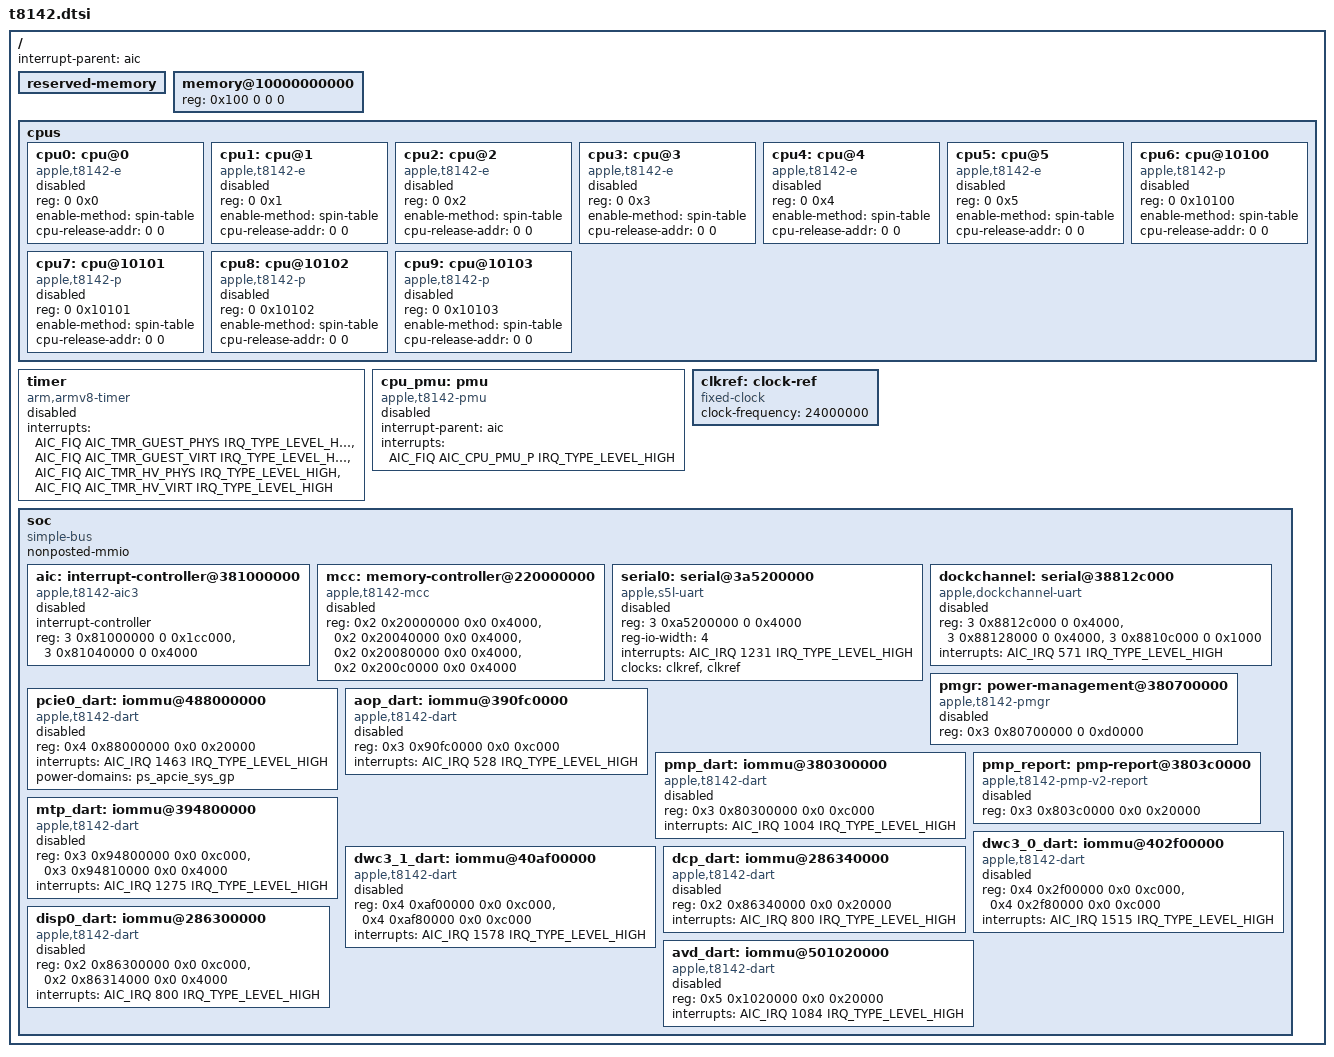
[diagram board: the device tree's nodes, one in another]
// SPDX-License-Identifier: GPL-2.0+ OR MIT
/*
 * Common hardware inventory for boards without a qualified boot profile.
 * Firmware fills RAM and CPU release addresses. Keep new devices disabled;
 * CPU harvesting, firmware handoff and enables need separate qualification.
 */
#include <dt-bindings/interrupt-controller/apple-aic.h>
#include <dt-bindings/interrupt-controller/irq.h>

/ {
	#address-cells = <2>;
	#size-cells = <2>;
	interrupt-parent = <&aic>;

	reserved-memory {
		#address-cells = <2>;
		#size-cells = <2>;
		ranges;
	};

	memory@10000000000 {
		device_type = "memory";
		reg = <0x100 0 0 0>; /* Filled by the loader. */
	};

	cpus {
		#address-cells = <2>;
		#size-cells = <0>;

		cpu0: cpu@0 {
			status = "disabled";
			compatible = "apple,t8142-e";
			device_type = "cpu";
			reg = <0 0x0>;
			enable-method = "spin-table";
			cpu-release-addr = <0 0>; /* Filled by the loader. */
			#cooling-cells = <2>;
		};

		cpu1: cpu@1 {
			status = "disabled";
			compatible = "apple,t8142-e";
			device_type = "cpu";
			reg = <0 0x1>;
			enable-method = "spin-table";
			cpu-release-addr = <0 0>; /* Filled by the loader. */
			#cooling-cells = <2>;
		};

		cpu2: cpu@2 {
			status = "disabled";
			compatible = "apple,t8142-e";
			device_type = "cpu";
			reg = <0 0x2>;
			enable-method = "spin-table";
			cpu-release-addr = <0 0>; /* Filled by the loader. */
			#cooling-cells = <2>;
		};

		cpu3: cpu@3 {
			status = "disabled";
			compatible = "apple,t8142-e";
			device_type = "cpu";
			reg = <0 0x3>;
			enable-method = "spin-table";
			cpu-release-addr = <0 0>; /* Filled by the loader. */
			#cooling-cells = <2>;
		};

		cpu4: cpu@4 {
			status = "disabled";
			compatible = "apple,t8142-e";
			device_type = "cpu";
			reg = <0 0x4>;
			enable-method = "spin-table";
			cpu-release-addr = <0 0>; /* Filled by the loader. */
			#cooling-cells = <2>;
		};

		cpu5: cpu@5 {
			status = "disabled";
			compatible = "apple,t8142-e";
			device_type = "cpu";
			reg = <0 0x5>;
			enable-method = "spin-table";
			cpu-release-addr = <0 0>; /* Filled by the loader. */
			#cooling-cells = <2>;
		};

		cpu6: cpu@10100 {
			status = "disabled";
			compatible = "apple,t8142-p";
			device_type = "cpu";
			reg = <0 0x10100>;
			enable-method = "spin-table";
			cpu-release-addr = <0 0>; /* Filled by the loader. */
			#cooling-cells = <2>;
		};

		cpu7: cpu@10101 {
			status = "disabled";
			compatible = "apple,t8142-p";
			device_type = "cpu";
			reg = <0 0x10101>;
			enable-method = "spin-table";
			cpu-release-addr = <0 0>; /* Filled by the loader. */
			#cooling-cells = <2>;
		};

		cpu8: cpu@10102 {
			status = "disabled";
			compatible = "apple,t8142-p";
			device_type = "cpu";
			reg = <0 0x10102>;
			enable-method = "spin-table";
			cpu-release-addr = <0 0>; /* Filled by the loader. */
			#cooling-cells = <2>;
		};

		cpu9: cpu@10103 {
			status = "disabled";
			compatible = "apple,t8142-p";
			device_type = "cpu";
			reg = <0 0x10103>;
			enable-method = "spin-table";
			cpu-release-addr = <0 0>; /* Filled by the loader. */
			#cooling-cells = <2>;
		};
	};

	timer {
		status = "disabled";
		compatible = "arm,armv8-timer";
		interrupts = <AIC_FIQ AIC_TMR_GUEST_PHYS IRQ_TYPE_LEVEL_HIGH>,
			     <AIC_FIQ AIC_TMR_GUEST_VIRT IRQ_TYPE_LEVEL_HIGH>,
			     <AIC_FIQ AIC_TMR_HV_PHYS IRQ_TYPE_LEVEL_HIGH>,
			     <AIC_FIQ AIC_TMR_HV_VIRT IRQ_TYPE_LEVEL_HIGH>;
		interrupt-names = "phys", "virt", "hyp-phys", "hyp-virt";
	};

	cpu_pmu: pmu {
		status = "disabled";
		compatible = "apple,t8142-pmu";
		interrupt-parent = <&aic>;
		/* The AIC raises both clusters' PMU FIQs as this one, as on T8140. */
		interrupts = <AIC_FIQ AIC_CPU_PMU_P IRQ_TYPE_LEVEL_HIGH>;
	};

	clkref: clock-ref {
		compatible = "fixed-clock";
		#clock-cells = <0>;
		clock-frequency = <24000000>;
	};

	soc {
		compatible = "simple-bus";
		#address-cells = <2>;
		#size-cells = <2>;
		ranges;
		nonposted-mmio;

		aic: interrupt-controller@381000000 {
			status = "disabled";
			compatible = "apple,t8142-aic3", "apple,t8122-aic3";
			interrupt-controller;
			#interrupt-cells = <3>;
			reg = <3 0x81000000 0 0x1cc000>,
			      <3 0x81040000 0 0x4000>;
			reg-names = "core", "event";
		};

		/*
		 * System level cache planes: ADT mcc,t8142 reg[1] (amcc-reg-idx 1,
		 * one AMCC, amcc-plane-enable-mask 0xf), four planes 0x40000 apart,
		 * T8140's register layout (ways 0x2800, power 0x2804, allocation
		 * disable 0x82c, flush 0x2844; m1n1/aura mcc_init_m5). aura enables
		 * the ways and allocation before the kernel, so the driver only
		 * checks that and flushes the cache on shutdown.
		 */
		mcc: memory-controller@220000000 {
			compatible = "apple,t8142-mcc", "apple,t8140-mcc";
			reg = <0x2 0x20000000 0x0 0x4000>,
			      <0x2 0x20040000 0x0 0x4000>,
			      <0x2 0x20080000 0x0 0x4000>,
			      <0x2 0x200c0000 0x0 0x4000>;
			status = "disabled";
		};

		serial0: serial@3a5200000 {
			status = "disabled";
			compatible = "apple,s5l-uart";
			reg = <3 0xa5200000 0 0x4000>;
			reg-io-width = <4>;
			interrupts = <AIC_IRQ 1231 IRQ_TYPE_LEVEL_HIGH>;
			clocks = <&clkref>, <&clkref>;
			clock-names = "uart", "clk_uart_baud0";
		};

		dockchannel: serial@38812c000 {
			status = "disabled";
			compatible = "apple,dockchannel-uart";
			reg = <3 0x8812c000 0 0x4000>,
			      <3 0x88128000 0 0x4000>,
			      <3 0x8810c000 0 0x1000>;
			reg-names = "data", "config", "irq";
			interrupts = <AIC_IRQ 571 IRQ_TYPE_LEVEL_HIGH>;
		};
	};
};

&{/soc} {
	pmgr: power-management@380700000 {
		compatible = "apple,t8142-pmgr", "apple,t8103-pmgr", "syscon", "simple-mfd";
		reg = <0x3 0x80700000 0 0xd0000>;
		#address-cells = <1>;
		#size-cells = <1>;
		status = "disabled";
	};
};

/* Native interfaces shared by the hardware-only board descriptions. */
&{/soc} {
	pcie0_dart: iommu@488000000 {
		compatible = "apple,t8142-dart", "apple,t8110-dart";
		reg = <0x4 0x88000000 0x0 0x20000>;
		interrupts = <AIC_IRQ 1463 IRQ_TYPE_LEVEL_HIGH>;
		#iommu-cells = <1>;
		power-domains = <&ps_apcie_sys_gp>;
		status = "disabled";
	};

	aop_dart: iommu@390fc0000 {
		compatible = "apple,t8142-dart", "apple,t8110-dart";
		reg = <0x3 0x90fc0000 0x0 0xc000>;
		interrupts = <AIC_IRQ 528 IRQ_TYPE_LEVEL_HIGH>;
		#iommu-cells = <1>;
		status = "disabled";
	};

	pmp_dart: iommu@380300000 {
		compatible = "apple,t8142-dart", "apple,t8110-dart";
		reg = <0x3 0x80300000 0x0 0xc000>;
		interrupts = <AIC_IRQ 1004 IRQ_TYPE_LEVEL_HIGH>;
		#iommu-cells = <1>;
		status = "disabled";
	};

	pmp_report: pmp-report@3803c0000 {
		compatible = "apple,t8142-pmp-v2-report";
		reg = <0x3 0x803c0000 0x0 0x20000>;
		#address-cells = <1>;
		#size-cells = <0>;
		status = "disabled";
	};

	mtp_dart: iommu@394800000 {
		compatible = "apple,t8142-dart", "apple,t8110-dart";
		reg = <0x3 0x94800000 0x0 0xc000>,
		      <0x3 0x94810000 0x0 0x4000>;
		reg-names = "dart", "dapf";
		interrupts = <AIC_IRQ 1275 IRQ_TYPE_LEVEL_HIGH>;
		#iommu-cells = <1>;
		status = "disabled";
	};

	dwc3_0_dart: iommu@402f00000 {
		compatible = "apple,t8142-dart", "apple,t8110-dart";
		reg = <0x4 0x2f00000 0x0 0xc000>,
		      <0x4 0x2f80000 0x0 0xc000>;
		interrupts = <AIC_IRQ 1515 IRQ_TYPE_LEVEL_HIGH>;
		#iommu-cells = <1>;
		status = "disabled";
	};

	dwc3_1_dart: iommu@40af00000 {
		compatible = "apple,t8142-dart", "apple,t8110-dart";
		reg = <0x4 0xaf00000 0x0 0xc000>,
		      <0x4 0xaf80000 0x0 0xc000>;
		interrupts = <AIC_IRQ 1578 IRQ_TYPE_LEVEL_HIGH>;
		#iommu-cells = <1>;
		status = "disabled";
	};

	dcp_dart: iommu@286340000 {
		compatible = "apple,t8142-dart", "apple,t8110-dart";
		reg = <0x2 0x86340000 0x0 0x20000>;
		interrupts = <AIC_IRQ 800 IRQ_TYPE_LEVEL_HIGH>;
		#iommu-cells = <1>;
		status = "disabled";
	};

	disp0_dart: iommu@286300000 {
		compatible = "apple,t8142-dart", "apple,t8110-dart";
		reg = <0x2 0x86300000 0x0 0xc000>,
		      <0x2 0x86314000 0x0 0x4000>;
		interrupts = <AIC_IRQ 800 IRQ_TYPE_LEVEL_HIGH>;
		#iommu-cells = <1>;
		status = "disabled";
	};

	avd_dart: iommu@501020000 {
		compatible = "apple,t8142-dart", "apple,t8110-dart";
		reg = <0x5 0x1020000 0x0 0x20000>;
		interrupts = <AIC_IRQ 1084 IRQ_TYPE_LEVEL_HIGH>;
		#iommu-cells = <1>;
		status = "disabled";
	};
};

#include "t8142-peripherals.dtsi"
